# RP2350 register map
Vendor: Raspberry Pi; Series: RP; File version: 0.1
CPU: CM33 r1p0, little endian, MPU, FPU, DSP, VTOR, 4 interrupt priority bits, 52 interrupts, 8 SAU regions
Registers are 32-bit, read-write, reset 0x0 unless marked. A register's access mark holds for its fields unless they carry their own. Offsets are from the block's base; [hi:lo] are bit positions; {n}, {i} and the like mark numbered series; 'fields as' and 'values as' point back to an identical list.

## IO_BANK0 — Peripheral description
Base 0x40028000
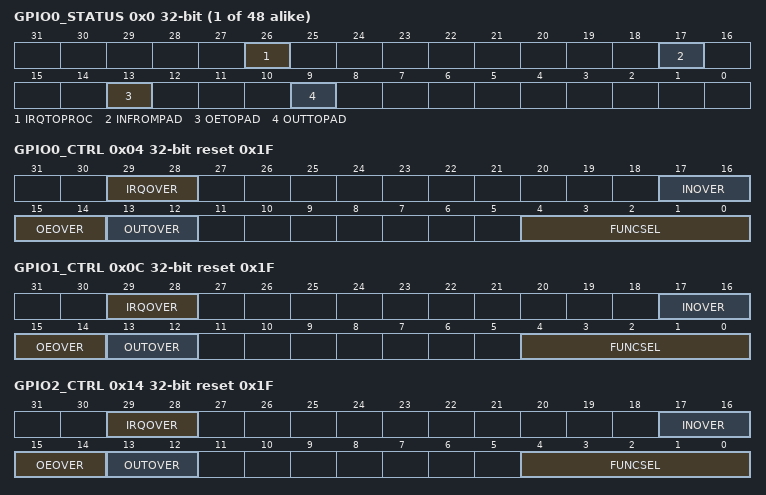
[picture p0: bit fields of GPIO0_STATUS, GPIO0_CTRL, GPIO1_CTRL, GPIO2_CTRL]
{0x0+8i} GPIO{i}_STATUS (i=0..47) — register description
  [26] IRQTOPROC ro — interrupt to processors, after override is applied
  [17] INFROMPAD ro — input signal from pad, before filtering and override are applied
  [13] OETOPAD ro — output enable to pad after register override is applied
  [9] OUTTOPAD ro — output signal to pad after register override is applied
0x04 GPIO0_CTRL reset 0x1F — register description
  [29:28] IRQOVER — Pre-defined description
    0=NORMAL (don't invert the interrupt); 1=INVERT (invert the interrupt); 2=LOW (drive interrupt low); 3=HIGH (drive interrupt high)
  [17:16] INOVER — Pre-defined description
    0=NORMAL (don't invert the peri input); 1=INVERT (invert the peri input); 2=LOW (drive peri input low); 3=HIGH (drive peri input high)
  [15:14] OEOVER — Pre-defined description
    0=NORMAL (drive output enable from peripheral signal selected by funcsel); 1=INVERT (drive output enable from inverse of peripheral signal selected by funcsel); 2=DISABLE (disable output); 3=ENABLE (enable output)
  [13:12] OUTOVER — Pre-defined description
    0=NORMAL (drive output from peripheral signal selected by funcsel); 1=INVERT (drive output from inverse of peripheral signal selected by funcsel); 2=LOW (drive output low); 3=HIGH (drive output high)
  [4:0] FUNCSEL — 0-31 -> selects pin function according to the gpio table 31 == NULL
    0=jtag_tck; 1=spi0_rx; 2=uart0_tx; 3=i2c0_sda; 4=pwm_a_0; 5=siob_proc_0; 6=pio0_0; 7=pio1_0; 8=pio2_0; 9=xip_ss_n_1; 10=usb_muxing_overcurr_detect; 31=null
0x0C GPIO1_CTRL reset 0x1F — register description
  [29:28] IRQOVER — Pre-defined description
    values as GPIO0_CTRL.IRQOVER
  [17:16] INOVER — Pre-defined description
    values as GPIO0_CTRL.INOVER
  [15:14] OEOVER — Pre-defined description
    values as GPIO0_CTRL.OEOVER
  [13:12] OUTOVER — Pre-defined description
    values as GPIO0_CTRL.OUTOVER
  [4:0] FUNCSEL — 0-31 -> selects pin function according to the gpio table 31 == NULL
    0=jtag_tms; 1=spi0_ss_n; 2=uart0_rx; 3=i2c0_scl; 4=pwm_b_0; 5=siob_proc_1; 6=pio0_1; 7=pio1_1; 8=pio2_1; 9=coresight_traceclk; 10=usb_muxing_vbus_detect; 31=null
0x14 GPIO2_CTRL reset 0x1F — register description
  [29:28] IRQOVER — Pre-defined description
    values as GPIO0_CTRL.IRQOVER
  [17:16] INOVER — Pre-defined description
    values as GPIO0_CTRL.INOVER
  [15:14] OEOVER — Pre-defined description
    values as GPIO0_CTRL.OEOVER
  [13:12] OUTOVER — Pre-defined description
    values as GPIO0_CTRL.OUTOVER
  [4:0] FUNCSEL — 0-31 -> selects pin function according to the gpio table 31 == NULL
    0=jtag_tdi; 1=spi0_sclk; 2=uart0_cts; 3=i2c1_sda; 4=pwm_a_1; 5=siob_proc_2; 6=pio0_2; 7=pio1_2; 8=pio2_2; 9=coresight_tracedata_0; 10=usb_muxing_vbus_en; 11=uart0_tx; 31=null
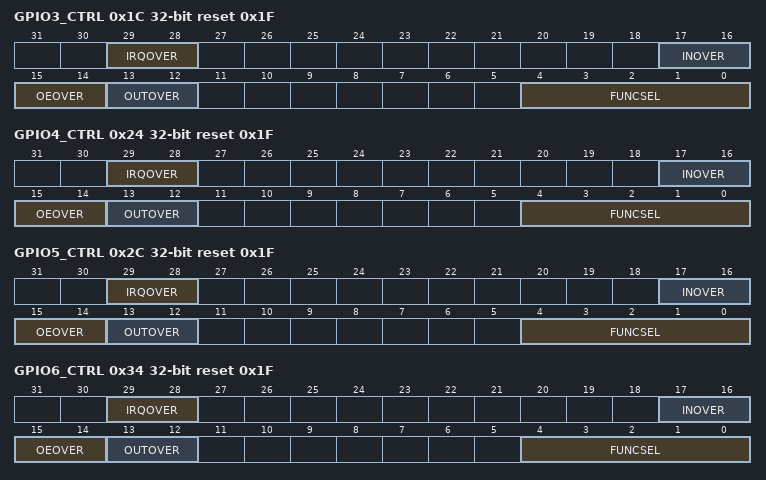
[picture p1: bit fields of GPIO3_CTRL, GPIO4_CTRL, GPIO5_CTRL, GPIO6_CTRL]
0x1C GPIO3_CTRL reset 0x1F — register description
  [29:28] IRQOVER — Pre-defined description
    values as GPIO0_CTRL.IRQOVER
  [17:16] INOVER — Pre-defined description
    values as GPIO0_CTRL.INOVER
  [15:14] OEOVER — Pre-defined description
    values as GPIO0_CTRL.OEOVER
  [13:12] OUTOVER — Pre-defined description
    values as GPIO0_CTRL.OUTOVER
  [4:0] FUNCSEL — 0-31 -> selects pin function according to the gpio table 31 == NULL
    0=jtag_tdo; 1=spi0_tx; 2=uart0_rts; 3=i2c1_scl; 4=pwm_b_1; 5=siob_proc_3; 6=pio0_3; 7=pio1_3; 8=pio2_3; 9=coresight_tracedata_1; 10=usb_muxing_overcurr_detect; 11=uart0_rx; 31=null
0x24 GPIO4_CTRL reset 0x1F — register description
  [29:28] IRQOVER — Pre-defined description
    values as GPIO0_CTRL.IRQOVER
  [17:16] INOVER — Pre-defined description
    values as GPIO0_CTRL.INOVER
  [15:14] OEOVER — Pre-defined description
    values as GPIO0_CTRL.OEOVER
  [13:12] OUTOVER — Pre-defined description
    values as GPIO0_CTRL.OUTOVER
  [4:0] FUNCSEL — 0-31 -> selects pin function according to the gpio table 31 == NULL
    1=spi0_rx; 2=uart1_tx; 3=i2c0_sda; 4=pwm_a_2; 5=siob_proc_4; 6=pio0_4; 7=pio1_4; 8=pio2_4; 9=coresight_tracedata_2; 10=usb_muxing_vbus_detect; 31=null
0x2C GPIO5_CTRL reset 0x1F — register description
  [29:28] IRQOVER — Pre-defined description
    values as GPIO0_CTRL.IRQOVER
  [17:16] INOVER — Pre-defined description
    values as GPIO0_CTRL.INOVER
  [15:14] OEOVER — Pre-defined description
    values as GPIO0_CTRL.OEOVER
  [13:12] OUTOVER — Pre-defined description
    values as GPIO0_CTRL.OUTOVER
  [4:0] FUNCSEL — 0-31 -> selects pin function according to the gpio table 31 == NULL
    1=spi0_ss_n; 2=uart1_rx; 3=i2c0_scl; 4=pwm_b_2; 5=siob_proc_5; 6=pio0_5; 7=pio1_5; 8=pio2_5; 9=coresight_tracedata_3; 10=usb_muxing_vbus_en; 31=null
0x34 GPIO6_CTRL reset 0x1F — register description
  [29:28] IRQOVER — Pre-defined description
    values as GPIO0_CTRL.IRQOVER
  [17:16] INOVER — Pre-defined description
    values as GPIO0_CTRL.INOVER
  [15:14] OEOVER — Pre-defined description
    values as GPIO0_CTRL.OEOVER
  [13:12] OUTOVER — Pre-defined description
    values as GPIO0_CTRL.OUTOVER
  [4:0] FUNCSEL — 0-31 -> selects pin function according to the gpio table 31 == NULL
    1=spi0_sclk; 2=uart1_cts; 3=i2c1_sda; 4=pwm_a_3; 5=siob_proc_6; 6=pio0_6; 7=pio1_6; 8=pio2_6; 10=usb_muxing_overcurr_detect; 11=uart1_tx; 31=null
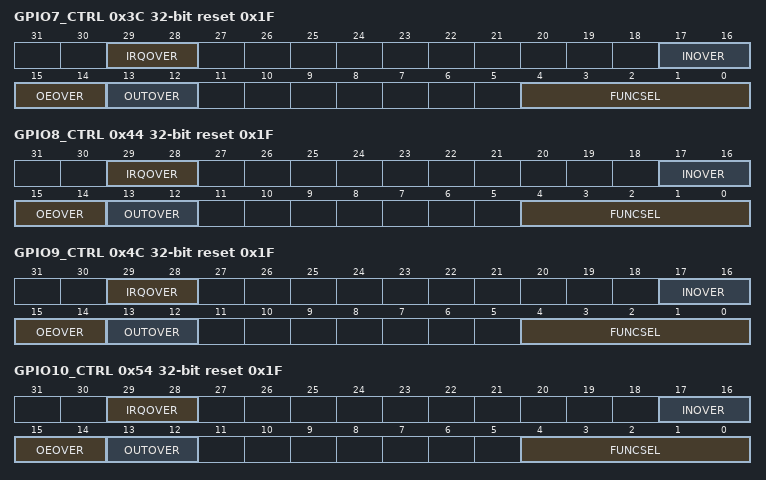
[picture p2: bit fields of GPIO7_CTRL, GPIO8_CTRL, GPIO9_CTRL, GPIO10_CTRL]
0x3C GPIO7_CTRL reset 0x1F — register description
  [29:28] IRQOVER — Pre-defined description
    values as GPIO0_CTRL.IRQOVER
  [17:16] INOVER — Pre-defined description
    values as GPIO0_CTRL.INOVER
  [15:14] OEOVER — Pre-defined description
    values as GPIO0_CTRL.OEOVER
  [13:12] OUTOVER — Pre-defined description
    values as GPIO0_CTRL.OUTOVER
  [4:0] FUNCSEL — 0-31 -> selects pin function according to the gpio table 31 == NULL
    1=spi0_tx; 2=uart1_rts; 3=i2c1_scl; 4=pwm_b_3; 5=siob_proc_7; 6=pio0_7; 7=pio1_7; 8=pio2_7; 10=usb_muxing_vbus_detect; 11=uart1_rx; 31=null
0x44 GPIO8_CTRL reset 0x1F — register description
  [29:28] IRQOVER — Pre-defined description
    values as GPIO0_CTRL.IRQOVER
  [17:16] INOVER — Pre-defined description
    values as GPIO0_CTRL.INOVER
  [15:14] OEOVER — Pre-defined description
    values as GPIO0_CTRL.OEOVER
  [13:12] OUTOVER — Pre-defined description
    values as GPIO0_CTRL.OUTOVER
  [4:0] FUNCSEL — 0-31 -> selects pin function according to the gpio table 31 == NULL
    1=spi1_rx; 2=uart1_tx; 3=i2c0_sda; 4=pwm_a_4; 5=siob_proc_8; 6=pio0_8; 7=pio1_8; 8=pio2_8; 9=xip_ss_n_1; 10=usb_muxing_vbus_en; 31=null
0x4C GPIO9_CTRL reset 0x1F — register description
  [29:28] IRQOVER — Pre-defined description
    values as GPIO0_CTRL.IRQOVER
  [17:16] INOVER — Pre-defined description
    values as GPIO0_CTRL.INOVER
  [15:14] OEOVER — Pre-defined description
    values as GPIO0_CTRL.OEOVER
  [13:12] OUTOVER — Pre-defined description
    values as GPIO0_CTRL.OUTOVER
  [4:0] FUNCSEL — 0-31 -> selects pin function according to the gpio table 31 == NULL
    1=spi1_ss_n; 2=uart1_rx; 3=i2c0_scl; 4=pwm_b_4; 5=siob_proc_9; 6=pio0_9; 7=pio1_9; 8=pio2_9; 10=usb_muxing_overcurr_detect; 31=null
0x54 GPIO10_CTRL reset 0x1F — register description
  [29:28] IRQOVER — Pre-defined description
    values as GPIO0_CTRL.IRQOVER
  [17:16] INOVER — Pre-defined description
    values as GPIO0_CTRL.INOVER
  [15:14] OEOVER — Pre-defined description
    values as GPIO0_CTRL.OEOVER
  [13:12] OUTOVER — Pre-defined description
    values as GPIO0_CTRL.OUTOVER
  [4:0] FUNCSEL — 0-31 -> selects pin function according to the gpio table 31 == NULL
    1=spi1_sclk; 2=uart1_cts; 3=i2c1_sda; 4=pwm_a_5; 5=siob_proc_10; 6=pio0_10; 7=pio1_10; 8=pio2_10; 10=usb_muxing_vbus_detect; 11=uart1_tx; 31=null
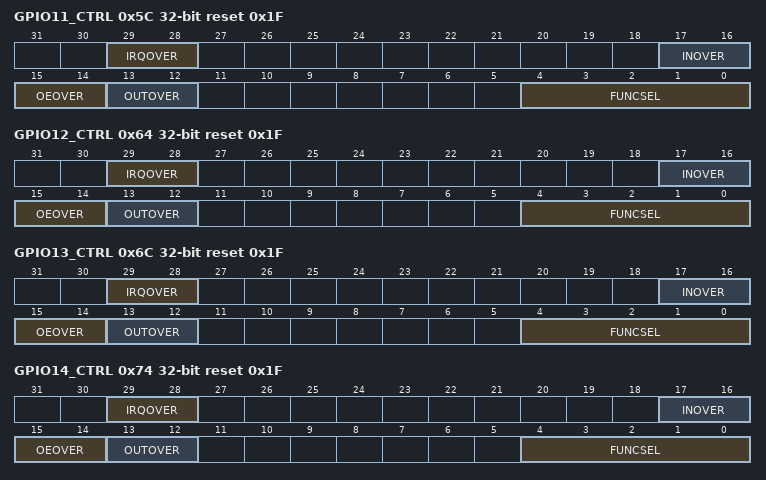
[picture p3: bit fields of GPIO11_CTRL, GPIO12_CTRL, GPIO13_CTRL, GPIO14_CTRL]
0x5C GPIO11_CTRL reset 0x1F — register description
  [29:28] IRQOVER — Pre-defined description
    values as GPIO0_CTRL.IRQOVER
  [17:16] INOVER — Pre-defined description
    values as GPIO0_CTRL.INOVER
  [15:14] OEOVER — Pre-defined description
    values as GPIO0_CTRL.OEOVER
  [13:12] OUTOVER — Pre-defined description
    values as GPIO0_CTRL.OUTOVER
  [4:0] FUNCSEL — 0-31 -> selects pin function according to the gpio table 31 == NULL
    1=spi1_tx; 2=uart1_rts; 3=i2c1_scl; 4=pwm_b_5; 5=siob_proc_11; 6=pio0_11; 7=pio1_11; 8=pio2_11; 10=usb_muxing_vbus_en; 11=uart1_rx; 31=null
0x64 GPIO12_CTRL reset 0x1F — register description
  [29:28] IRQOVER — Pre-defined description
    values as GPIO0_CTRL.IRQOVER
  [17:16] INOVER — Pre-defined description
    values as GPIO0_CTRL.INOVER
  [15:14] OEOVER — Pre-defined description
    values as GPIO0_CTRL.OEOVER
  [13:12] OUTOVER — Pre-defined description
    values as GPIO0_CTRL.OUTOVER
  [4:0] FUNCSEL — 0-31 -> selects pin function according to the gpio table 31 == NULL
    0=hstx_0; 1=spi1_rx; 2=uart0_tx; 3=i2c0_sda; 4=pwm_a_6; 5=siob_proc_12; 6=pio0_12; 7=pio1_12; 8=pio2_12; 9=clocks_gpin_0; 10=usb_muxing_overcurr_detect; 31=null
0x6C GPIO13_CTRL reset 0x1F — register description
  [29:28] IRQOVER — Pre-defined description
    values as GPIO0_CTRL.IRQOVER
  [17:16] INOVER — Pre-defined description
    values as GPIO0_CTRL.INOVER
  [15:14] OEOVER — Pre-defined description
    values as GPIO0_CTRL.OEOVER
  [13:12] OUTOVER — Pre-defined description
    values as GPIO0_CTRL.OUTOVER
  [4:0] FUNCSEL — 0-31 -> selects pin function according to the gpio table 31 == NULL
    0=hstx_1; 1=spi1_ss_n; 2=uart0_rx; 3=i2c0_scl; 4=pwm_b_6; 5=siob_proc_13; 6=pio0_13; 7=pio1_13; 8=pio2_13; 9=clocks_gpout_0; 10=usb_muxing_vbus_detect; 31=null
0x74 GPIO14_CTRL reset 0x1F — register description
  [29:28] IRQOVER — Pre-defined description
    values as GPIO0_CTRL.IRQOVER
  [17:16] INOVER — Pre-defined description
    values as GPIO0_CTRL.INOVER
  [15:14] OEOVER — Pre-defined description
    values as GPIO0_CTRL.OEOVER
  [13:12] OUTOVER — Pre-defined description
    values as GPIO0_CTRL.OUTOVER
  [4:0] FUNCSEL — 0-31 -> selects pin function according to the gpio table 31 == NULL
    0=hstx_2; 1=spi1_sclk; 2=uart0_cts; 3=i2c1_sda; 4=pwm_a_7; 5=siob_proc_14; 6=pio0_14; 7=pio1_14; 8=pio2_14; 9=clocks_gpin_1; 10=usb_muxing_vbus_en; 11=uart0_tx; 31=null
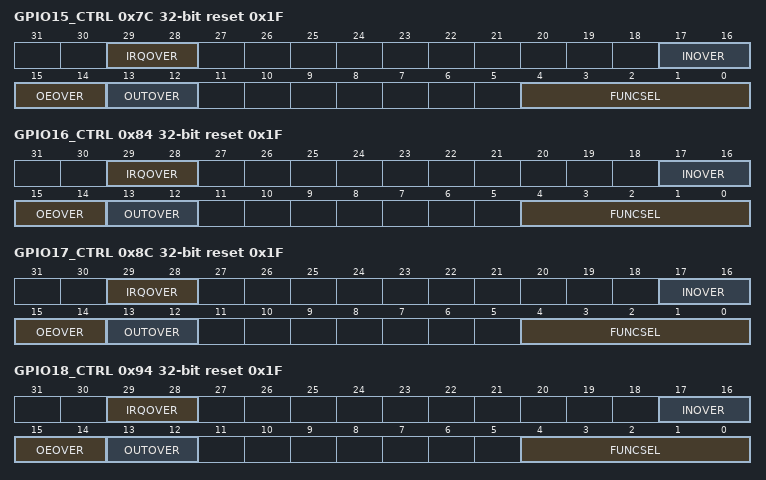
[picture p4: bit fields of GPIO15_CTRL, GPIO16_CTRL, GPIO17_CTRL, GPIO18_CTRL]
0x7C GPIO15_CTRL reset 0x1F — register description
  [29:28] IRQOVER — Pre-defined description
    values as GPIO0_CTRL.IRQOVER
  [17:16] INOVER — Pre-defined description
    values as GPIO0_CTRL.INOVER
  [15:14] OEOVER — Pre-defined description
    values as GPIO0_CTRL.OEOVER
  [13:12] OUTOVER — Pre-defined description
    values as GPIO0_CTRL.OUTOVER
  [4:0] FUNCSEL — 0-31 -> selects pin function according to the gpio table 31 == NULL
    0=hstx_3; 1=spi1_tx; 2=uart0_rts; 3=i2c1_scl; 4=pwm_b_7; 5=siob_proc_15; 6=pio0_15; 7=pio1_15; 8=pio2_15; 9=clocks_gpout_1; 10=usb_muxing_overcurr_detect; 11=uart0_rx; 31=null
0x84 GPIO16_CTRL reset 0x1F — register description
  [29:28] IRQOVER — Pre-defined description
    values as GPIO0_CTRL.IRQOVER
  [17:16] INOVER — Pre-defined description
    values as GPIO0_CTRL.INOVER
  [15:14] OEOVER — Pre-defined description
    values as GPIO0_CTRL.OEOVER
  [13:12] OUTOVER — Pre-defined description
    values as GPIO0_CTRL.OUTOVER
  [4:0] FUNCSEL — 0-31 -> selects pin function according to the gpio table 31 == NULL
    0=hstx_4; 1=spi0_rx; 2=uart0_tx; 3=i2c0_sda; 4=pwm_a_0; 5=siob_proc_16; 6=pio0_16; 7=pio1_16; 8=pio2_16; 10=usb_muxing_vbus_detect; 31=null
0x8C GPIO17_CTRL reset 0x1F — register description
  [29:28] IRQOVER — Pre-defined description
    values as GPIO0_CTRL.IRQOVER
  [17:16] INOVER — Pre-defined description
    values as GPIO0_CTRL.INOVER
  [15:14] OEOVER — Pre-defined description
    values as GPIO0_CTRL.OEOVER
  [13:12] OUTOVER — Pre-defined description
    values as GPIO0_CTRL.OUTOVER
  [4:0] FUNCSEL — 0-31 -> selects pin function according to the gpio table 31 == NULL
    0=hstx_5; 1=spi0_ss_n; 2=uart0_rx; 3=i2c0_scl; 4=pwm_b_0; 5=siob_proc_17; 6=pio0_17; 7=pio1_17; 8=pio2_17; 10=usb_muxing_vbus_en; 31=null
0x94 GPIO18_CTRL reset 0x1F — register description
  [29:28] IRQOVER — Pre-defined description
    values as GPIO0_CTRL.IRQOVER
  [17:16] INOVER — Pre-defined description
    values as GPIO0_CTRL.INOVER
  [15:14] OEOVER — Pre-defined description
    values as GPIO0_CTRL.OEOVER
  [13:12] OUTOVER — Pre-defined description
    values as GPIO0_CTRL.OUTOVER
  [4:0] FUNCSEL — 0-31 -> selects pin function according to the gpio table 31 == NULL
    0=hstx_6; 1=spi0_sclk; 2=uart0_cts; 3=i2c1_sda; 4=pwm_a_1; 5=siob_proc_18; 6=pio0_18; 7=pio1_18; 8=pio2_18; 10=usb_muxing_overcurr_detect; 11=uart0_tx; 31=null
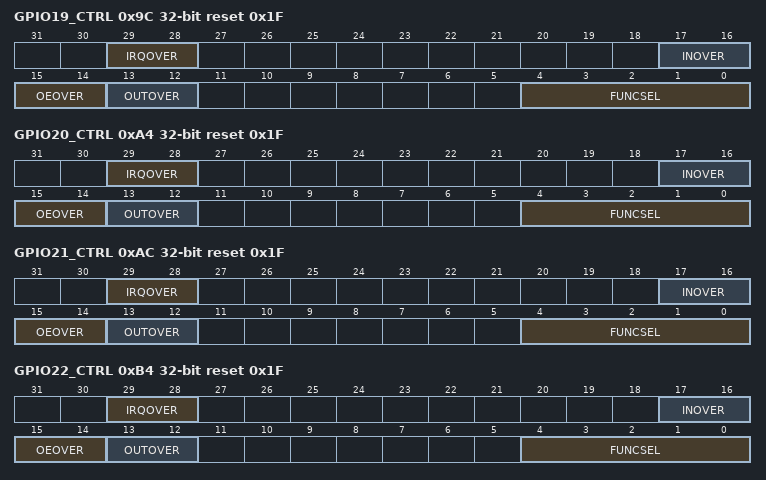
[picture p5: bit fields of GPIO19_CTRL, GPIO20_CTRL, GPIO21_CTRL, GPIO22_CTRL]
0x9C GPIO19_CTRL reset 0x1F — register description
  [29:28] IRQOVER — Pre-defined description
    values as GPIO0_CTRL.IRQOVER
  [17:16] INOVER — Pre-defined description
    values as GPIO0_CTRL.INOVER
  [15:14] OEOVER — Pre-defined description
    values as GPIO0_CTRL.OEOVER
  [13:12] OUTOVER — Pre-defined description
    values as GPIO0_CTRL.OUTOVER
  [4:0] FUNCSEL — 0-31 -> selects pin function according to the gpio table 31 == NULL
    0=hstx_7; 1=spi0_tx; 2=uart0_rts; 3=i2c1_scl; 4=pwm_b_1; 5=siob_proc_19; 6=pio0_19; 7=pio1_19; 8=pio2_19; 9=xip_ss_n_1; 10=usb_muxing_vbus_detect; 11=uart0_rx; 31=null
0xA4 GPIO20_CTRL reset 0x1F — register description
  [29:28] IRQOVER — Pre-defined description
    values as GPIO0_CTRL.IRQOVER
  [17:16] INOVER — Pre-defined description
    values as GPIO0_CTRL.INOVER
  [15:14] OEOVER — Pre-defined description
    values as GPIO0_CTRL.OEOVER
  [13:12] OUTOVER — Pre-defined description
    values as GPIO0_CTRL.OUTOVER
  [4:0] FUNCSEL — 0-31 -> selects pin function according to the gpio table 31 == NULL
    1=spi0_rx; 2=uart1_tx; 3=i2c0_sda; 4=pwm_a_2; 5=siob_proc_20; 6=pio0_20; 7=pio1_20; 8=pio2_20; 9=clocks_gpin_0; 10=usb_muxing_vbus_en; 31=null
0xAC GPIO21_CTRL reset 0x1F — register description
  [29:28] IRQOVER — Pre-defined description
    values as GPIO0_CTRL.IRQOVER
  [17:16] INOVER — Pre-defined description
    values as GPIO0_CTRL.INOVER
  [15:14] OEOVER — Pre-defined description
    values as GPIO0_CTRL.OEOVER
  [13:12] OUTOVER — Pre-defined description
    values as GPIO0_CTRL.OUTOVER
  [4:0] FUNCSEL — 0-31 -> selects pin function according to the gpio table 31 == NULL
    1=spi0_ss_n; 2=uart1_rx; 3=i2c0_scl; 4=pwm_b_2; 5=siob_proc_21; 6=pio0_21; 7=pio1_21; 8=pio2_21; 9=clocks_gpout_0; 10=usb_muxing_overcurr_detect; 31=null
0xB4 GPIO22_CTRL reset 0x1F — register description
  [29:28] IRQOVER — Pre-defined description
    values as GPIO0_CTRL.IRQOVER
  [17:16] INOVER — Pre-defined description
    values as GPIO0_CTRL.INOVER
  [15:14] OEOVER — Pre-defined description
    values as GPIO0_CTRL.OEOVER
  [13:12] OUTOVER — Pre-defined description
    values as GPIO0_CTRL.OUTOVER
  [4:0] FUNCSEL — 0-31 -> selects pin function according to the gpio table 31 == NULL
    1=spi0_sclk; 2=uart1_cts; 3=i2c1_sda; 4=pwm_a_3; 5=siob_proc_22; 6=pio0_22; 7=pio1_22; 8=pio2_22; 9=clocks_gpin_1; 10=usb_muxing_vbus_detect; 11=uart1_tx; 31=null
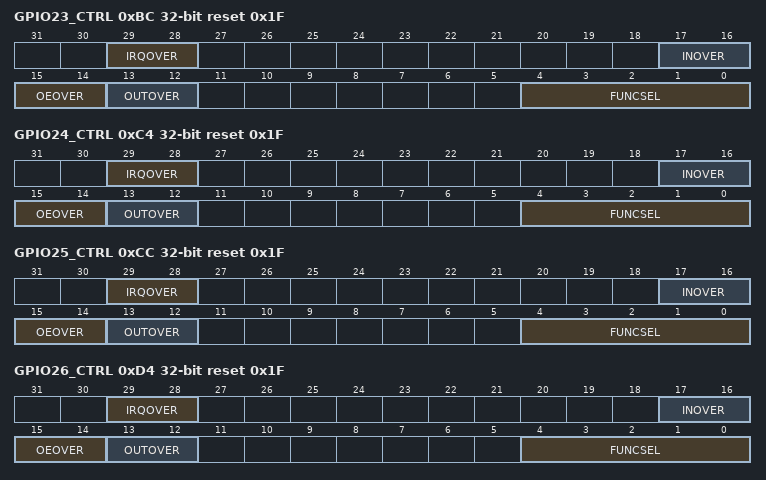
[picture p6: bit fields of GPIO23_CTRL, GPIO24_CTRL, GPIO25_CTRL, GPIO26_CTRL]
0xBC GPIO23_CTRL reset 0x1F — register description
  [29:28] IRQOVER — Pre-defined description
    values as GPIO0_CTRL.IRQOVER
  [17:16] INOVER — Pre-defined description
    values as GPIO0_CTRL.INOVER
  [15:14] OEOVER — Pre-defined description
    values as GPIO0_CTRL.OEOVER
  [13:12] OUTOVER — Pre-defined description
    values as GPIO0_CTRL.OUTOVER
  [4:0] FUNCSEL — 0-31 -> selects pin function according to the gpio table 31 == NULL
    1=spi0_tx; 2=uart1_rts; 3=i2c1_scl; 4=pwm_b_3; 5=siob_proc_23; 6=pio0_23; 7=pio1_23; 8=pio2_23; 9=clocks_gpout_1; 10=usb_muxing_vbus_en; 11=uart1_rx; 31=null
0xC4 GPIO24_CTRL reset 0x1F — register description
  [29:28] IRQOVER — Pre-defined description
    values as GPIO0_CTRL.IRQOVER
  [17:16] INOVER — Pre-defined description
    values as GPIO0_CTRL.INOVER
  [15:14] OEOVER — Pre-defined description
    values as GPIO0_CTRL.OEOVER
  [13:12] OUTOVER — Pre-defined description
    values as GPIO0_CTRL.OUTOVER
  [4:0] FUNCSEL — 0-31 -> selects pin function according to the gpio table 31 == NULL
    1=spi1_rx; 2=uart1_tx; 3=i2c0_sda; 4=pwm_a_4; 5=siob_proc_24; 6=pio0_24; 7=pio1_24; 8=pio2_24; 9=clocks_gpout_2; 10=usb_muxing_overcurr_detect; 31=null
0xCC GPIO25_CTRL reset 0x1F — register description
  [29:28] IRQOVER — Pre-defined description
    values as GPIO0_CTRL.IRQOVER
  [17:16] INOVER — Pre-defined description
    values as GPIO0_CTRL.INOVER
  [15:14] OEOVER — Pre-defined description
    values as GPIO0_CTRL.OEOVER
  [13:12] OUTOVER — Pre-defined description
    values as GPIO0_CTRL.OUTOVER
  [4:0] FUNCSEL — 0-31 -> selects pin function according to the gpio table 31 == NULL
    1=spi1_ss_n; 2=uart1_rx; 3=i2c0_scl; 4=pwm_b_4; 5=siob_proc_25; 6=pio0_25; 7=pio1_25; 8=pio2_25; 9=clocks_gpout_3; 10=usb_muxing_vbus_detect; 31=null
0xD4 GPIO26_CTRL reset 0x1F — register description
  [29:28] IRQOVER — Pre-defined description
    values as GPIO0_CTRL.IRQOVER
  [17:16] INOVER — Pre-defined description
    values as GPIO0_CTRL.INOVER
  [15:14] OEOVER — Pre-defined description
    values as GPIO0_CTRL.OEOVER
  [13:12] OUTOVER — Pre-defined description
    values as GPIO0_CTRL.OUTOVER
  [4:0] FUNCSEL — 0-31 -> selects pin function according to the gpio table 31 == NULL
    1=spi1_sclk; 2=uart1_cts; 3=i2c1_sda; 4=pwm_a_5; 5=siob_proc_26; 6=pio0_26; 7=pio1_26; 8=pio2_26; 10=usb_muxing_vbus_en; 11=uart1_tx; 31=null
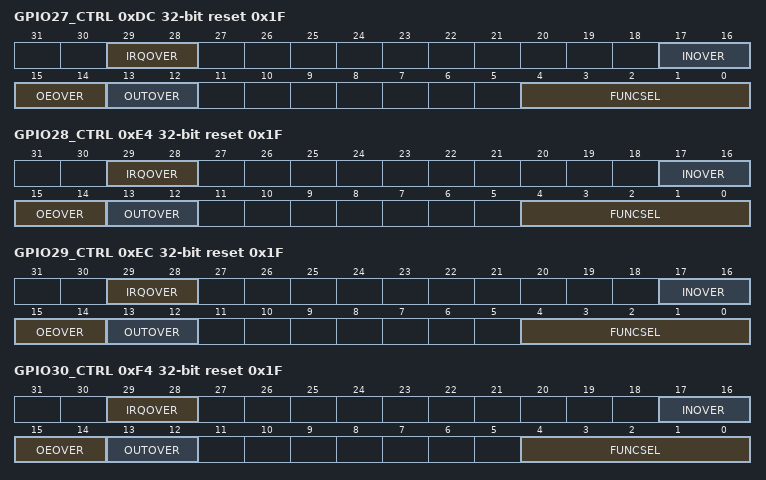
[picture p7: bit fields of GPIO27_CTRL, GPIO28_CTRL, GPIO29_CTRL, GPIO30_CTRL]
0xDC GPIO27_CTRL reset 0x1F — register description
  [29:28] IRQOVER — Pre-defined description
    values as GPIO0_CTRL.IRQOVER
  [17:16] INOVER — Pre-defined description
    values as GPIO0_CTRL.INOVER
  [15:14] OEOVER — Pre-defined description
    values as GPIO0_CTRL.OEOVER
  [13:12] OUTOVER — Pre-defined description
    values as GPIO0_CTRL.OUTOVER
  [4:0] FUNCSEL — 0-31 -> selects pin function according to the gpio table 31 == NULL
    1=spi1_tx; 2=uart1_rts; 3=i2c1_scl; 4=pwm_b_5; 5=siob_proc_27; 6=pio0_27; 7=pio1_27; 8=pio2_27; 10=usb_muxing_overcurr_detect; 11=uart1_rx; 31=null
0xE4 GPIO28_CTRL reset 0x1F — register description
  [29:28] IRQOVER — Pre-defined description
    values as GPIO0_CTRL.IRQOVER
  [17:16] INOVER — Pre-defined description
    values as GPIO0_CTRL.INOVER
  [15:14] OEOVER — Pre-defined description
    values as GPIO0_CTRL.OEOVER
  [13:12] OUTOVER — Pre-defined description
    values as GPIO0_CTRL.OUTOVER
  [4:0] FUNCSEL — 0-31 -> selects pin function according to the gpio table 31 == NULL
    1=spi1_rx; 2=uart0_tx; 3=i2c0_sda; 4=pwm_a_6; 5=siob_proc_28; 6=pio0_28; 7=pio1_28; 8=pio2_28; 10=usb_muxing_vbus_detect; 31=null
0xEC GPIO29_CTRL reset 0x1F — register description
  [29:28] IRQOVER — Pre-defined description
    values as GPIO0_CTRL.IRQOVER
  [17:16] INOVER — Pre-defined description
    values as GPIO0_CTRL.INOVER
  [15:14] OEOVER — Pre-defined description
    values as GPIO0_CTRL.OEOVER
  [13:12] OUTOVER — Pre-defined description
    values as GPIO0_CTRL.OUTOVER
  [4:0] FUNCSEL — 0-31 -> selects pin function according to the gpio table 31 == NULL
    1=spi1_ss_n; 2=uart0_rx; 3=i2c0_scl; 4=pwm_b_6; 5=siob_proc_29; 6=pio0_29; 7=pio1_29; 8=pio2_29; 10=usb_muxing_vbus_en; 31=null
0xF4 GPIO30_CTRL reset 0x1F — register description
  [29:28] IRQOVER — Pre-defined description
    values as GPIO0_CTRL.IRQOVER
  [17:16] INOVER — Pre-defined description
    values as GPIO0_CTRL.INOVER
  [15:14] OEOVER — Pre-defined description
    values as GPIO0_CTRL.OEOVER
  [13:12] OUTOVER — Pre-defined description
    values as GPIO0_CTRL.OUTOVER
  [4:0] FUNCSEL — 0-31 -> selects pin function according to the gpio table 31 == NULL
    1=spi1_sclk; 2=uart0_cts; 3=i2c1_sda; 4=pwm_a_7; 5=siob_proc_30; 6=pio0_30; 7=pio1_30; 8=pio2_30; 10=usb_muxing_overcurr_detect; 11=uart0_tx; 31=null
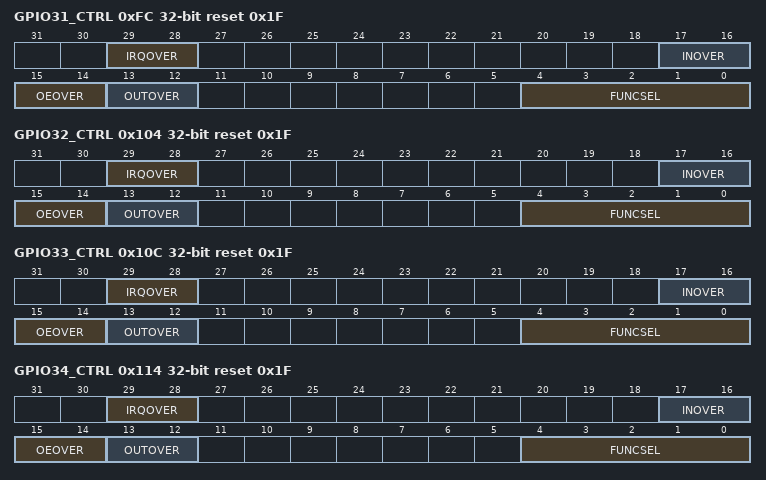
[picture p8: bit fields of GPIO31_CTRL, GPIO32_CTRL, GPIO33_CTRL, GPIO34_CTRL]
0xFC GPIO31_CTRL reset 0x1F — register description
  [29:28] IRQOVER — Pre-defined description
    values as GPIO0_CTRL.IRQOVER
  [17:16] INOVER — Pre-defined description
    values as GPIO0_CTRL.INOVER
  [15:14] OEOVER — Pre-defined description
    values as GPIO0_CTRL.OEOVER
  [13:12] OUTOVER — Pre-defined description
    values as GPIO0_CTRL.OUTOVER
  [4:0] FUNCSEL — 0-31 -> selects pin function according to the gpio table 31 == NULL
    1=spi1_tx; 2=uart0_rts; 3=i2c1_scl; 4=pwm_b_7; 5=siob_proc_31; 6=pio0_31; 7=pio1_31; 8=pio2_31; 10=usb_muxing_vbus_detect; 11=uart0_rx; 31=null
0x104 GPIO32_CTRL reset 0x1F — register description
  [29:28] IRQOVER — Pre-defined description
    values as GPIO0_CTRL.IRQOVER
  [17:16] INOVER — Pre-defined description
    values as GPIO0_CTRL.INOVER
  [15:14] OEOVER — Pre-defined description
    values as GPIO0_CTRL.OEOVER
  [13:12] OUTOVER — Pre-defined description
    values as GPIO0_CTRL.OUTOVER
  [4:0] FUNCSEL — 0-31 -> selects pin function according to the gpio table 31 == NULL
    1=spi0_rx; 2=uart0_tx; 3=i2c0_sda; 4=pwm_a_8; 5=siob_proc_32; 6=pio0_32; 7=pio1_32; 8=pio2_32; 10=usb_muxing_vbus_en; 31=null
0x10C GPIO33_CTRL reset 0x1F — register description
  [29:28] IRQOVER — Pre-defined description
    values as GPIO0_CTRL.IRQOVER
  [17:16] INOVER — Pre-defined description
    values as GPIO0_CTRL.INOVER
  [15:14] OEOVER — Pre-defined description
    values as GPIO0_CTRL.OEOVER
  [13:12] OUTOVER — Pre-defined description
    values as GPIO0_CTRL.OUTOVER
  [4:0] FUNCSEL — 0-31 -> selects pin function according to the gpio table 31 == NULL
    1=spi0_ss_n; 2=uart0_rx; 3=i2c0_scl; 4=pwm_b_8; 5=siob_proc_33; 6=pio0_33; 7=pio1_33; 8=pio2_33; 10=usb_muxing_overcurr_detect; 31=null
0x114 GPIO34_CTRL reset 0x1F — register description
  [29:28] IRQOVER — Pre-defined description
    values as GPIO0_CTRL.IRQOVER
  [17:16] INOVER — Pre-defined description
    values as GPIO0_CTRL.INOVER
  [15:14] OEOVER — Pre-defined description
    values as GPIO0_CTRL.OEOVER
  [13:12] OUTOVER — Pre-defined description
    values as GPIO0_CTRL.OUTOVER
  [4:0] FUNCSEL — 0-31 -> selects pin function according to the gpio table 31 == NULL
    1=spi0_sclk; 2=uart0_cts; 3=i2c1_sda; 4=pwm_a_9; 5=siob_proc_34; 6=pio0_34; 7=pio1_34; 8=pio2_34; 10=usb_muxing_vbus_detect; 11=uart0_tx; 31=null
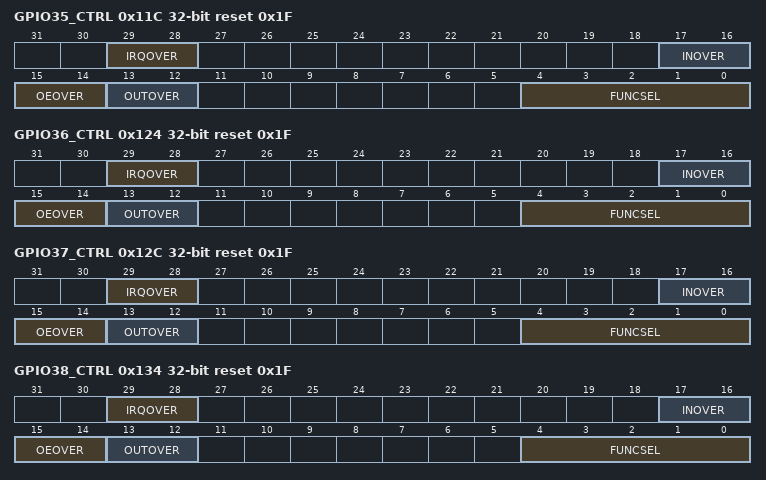
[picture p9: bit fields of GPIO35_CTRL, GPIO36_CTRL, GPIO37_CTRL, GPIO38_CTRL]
0x11C GPIO35_CTRL reset 0x1F — register description
  [29:28] IRQOVER — Pre-defined description
    values as GPIO0_CTRL.IRQOVER
  [17:16] INOVER — Pre-defined description
    values as GPIO0_CTRL.INOVER
  [15:14] OEOVER — Pre-defined description
    values as GPIO0_CTRL.OEOVER
  [13:12] OUTOVER — Pre-defined description
    values as GPIO0_CTRL.OUTOVER
  [4:0] FUNCSEL — 0-31 -> selects pin function according to the gpio table 31 == NULL
    1=spi0_tx; 2=uart0_rts; 3=i2c1_scl; 4=pwm_b_9; 5=siob_proc_35; 6=pio0_35; 7=pio1_35; 8=pio2_35; 10=usb_muxing_vbus_en; 11=uart0_rx; 31=null
0x124 GPIO36_CTRL reset 0x1F — register description
  [29:28] IRQOVER — Pre-defined description
    values as GPIO0_CTRL.IRQOVER
  [17:16] INOVER — Pre-defined description
    values as GPIO0_CTRL.INOVER
  [15:14] OEOVER — Pre-defined description
    values as GPIO0_CTRL.OEOVER
  [13:12] OUTOVER — Pre-defined description
    values as GPIO0_CTRL.OUTOVER
  [4:0] FUNCSEL — 0-31 -> selects pin function according to the gpio table 31 == NULL
    1=spi0_rx; 2=uart1_tx; 3=i2c0_sda; 4=pwm_a_10; 5=siob_proc_36; 6=pio0_36; 7=pio1_36; 8=pio2_36; 10=usb_muxing_overcurr_detect; 31=null
0x12C GPIO37_CTRL reset 0x1F — register description
  [29:28] IRQOVER — Pre-defined description
    values as GPIO0_CTRL.IRQOVER
  [17:16] INOVER — Pre-defined description
    values as GPIO0_CTRL.INOVER
  [15:14] OEOVER — Pre-defined description
    values as GPIO0_CTRL.OEOVER
  [13:12] OUTOVER — Pre-defined description
    values as GPIO0_CTRL.OUTOVER
  [4:0] FUNCSEL — 0-31 -> selects pin function according to the gpio table 31 == NULL
    1=spi0_ss_n; 2=uart1_rx; 3=i2c0_scl; 4=pwm_b_10; 5=siob_proc_37; 6=pio0_37; 7=pio1_37; 8=pio2_37; 10=usb_muxing_vbus_detect; 31=null
0x134 GPIO38_CTRL reset 0x1F — register description
  [29:28] IRQOVER — Pre-defined description
    values as GPIO0_CTRL.IRQOVER
  [17:16] INOVER — Pre-defined description
    values as GPIO0_CTRL.INOVER
  [15:14] OEOVER — Pre-defined description
    values as GPIO0_CTRL.OEOVER
  [13:12] OUTOVER — Pre-defined description
    values as GPIO0_CTRL.OUTOVER
  [4:0] FUNCSEL — 0-31 -> selects pin function according to the gpio table 31 == NULL
    1=spi0_sclk; 2=uart1_cts; 3=i2c1_sda; 4=pwm_a_11; 5=siob_proc_38; 6=pio0_38; 7=pio1_38; 8=pio2_38; 10=usb_muxing_vbus_en; 11=uart1_tx; 31=null
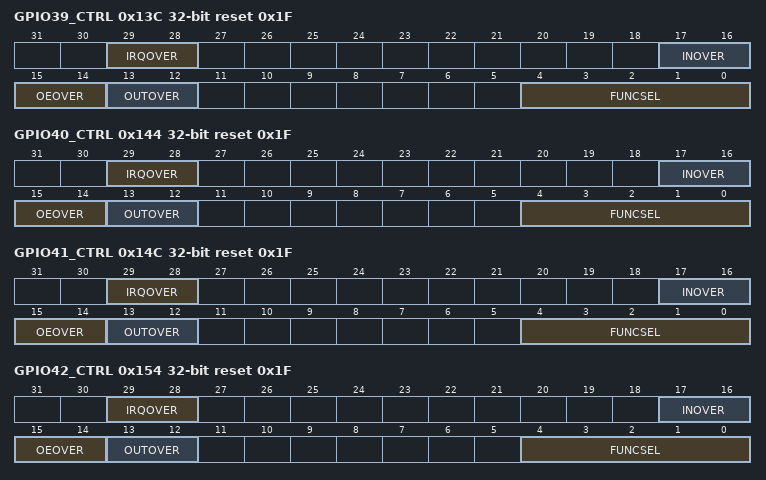
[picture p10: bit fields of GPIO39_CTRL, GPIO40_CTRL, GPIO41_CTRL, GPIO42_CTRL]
0x13C GPIO39_CTRL reset 0x1F — register description
  [29:28] IRQOVER — Pre-defined description
    values as GPIO0_CTRL.IRQOVER
  [17:16] INOVER — Pre-defined description
    values as GPIO0_CTRL.INOVER
  [15:14] OEOVER — Pre-defined description
    values as GPIO0_CTRL.OEOVER
  [13:12] OUTOVER — Pre-defined description
    values as GPIO0_CTRL.OUTOVER
  [4:0] FUNCSEL — 0-31 -> selects pin function according to the gpio table 31 == NULL
    1=spi0_tx; 2=uart1_rts; 3=i2c1_scl; 4=pwm_b_11; 5=siob_proc_39; 6=pio0_39; 7=pio1_39; 8=pio2_39; 10=usb_muxing_overcurr_detect; 11=uart1_rx; 31=null
0x144 GPIO40_CTRL reset 0x1F — register description
  [29:28] IRQOVER — Pre-defined description
    values as GPIO0_CTRL.IRQOVER
  [17:16] INOVER — Pre-defined description
    values as GPIO0_CTRL.INOVER
  [15:14] OEOVER — Pre-defined description
    values as GPIO0_CTRL.OEOVER
  [13:12] OUTOVER — Pre-defined description
    values as GPIO0_CTRL.OUTOVER
  [4:0] FUNCSEL — 0-31 -> selects pin function according to the gpio table 31 == NULL
    1=spi1_rx; 2=uart1_tx; 3=i2c0_sda; 4=pwm_a_8; 5=siob_proc_40; 6=pio0_40; 7=pio1_40; 8=pio2_40; 10=usb_muxing_vbus_detect; 31=null
0x14C GPIO41_CTRL reset 0x1F — register description
  [29:28] IRQOVER — Pre-defined description
    values as GPIO0_CTRL.IRQOVER
  [17:16] INOVER — Pre-defined description
    values as GPIO0_CTRL.INOVER
  [15:14] OEOVER — Pre-defined description
    values as GPIO0_CTRL.OEOVER
  [13:12] OUTOVER — Pre-defined description
    values as GPIO0_CTRL.OUTOVER
  [4:0] FUNCSEL — 0-31 -> selects pin function according to the gpio table 31 == NULL
    1=spi1_ss_n; 2=uart1_rx; 3=i2c0_scl; 4=pwm_b_8; 5=siob_proc_41; 6=pio0_41; 7=pio1_41; 8=pio2_41; 10=usb_muxing_vbus_en; 31=null
0x154 GPIO42_CTRL reset 0x1F — register description
  [29:28] IRQOVER — Pre-defined description
    values as GPIO0_CTRL.IRQOVER
  [17:16] INOVER — Pre-defined description
    values as GPIO0_CTRL.INOVER
  [15:14] OEOVER — Pre-defined description
    values as GPIO0_CTRL.OEOVER
  [13:12] OUTOVER — Pre-defined description
    values as GPIO0_CTRL.OUTOVER
  [4:0] FUNCSEL — 0-31 -> selects pin function according to the gpio table 31 == NULL
    1=spi1_sclk; 2=uart1_cts; 3=i2c1_sda; 4=pwm_a_9; 5=siob_proc_42; 6=pio0_42; 7=pio1_42; 8=pio2_42; 10=usb_muxing_overcurr_detect; 11=uart1_tx; 31=null
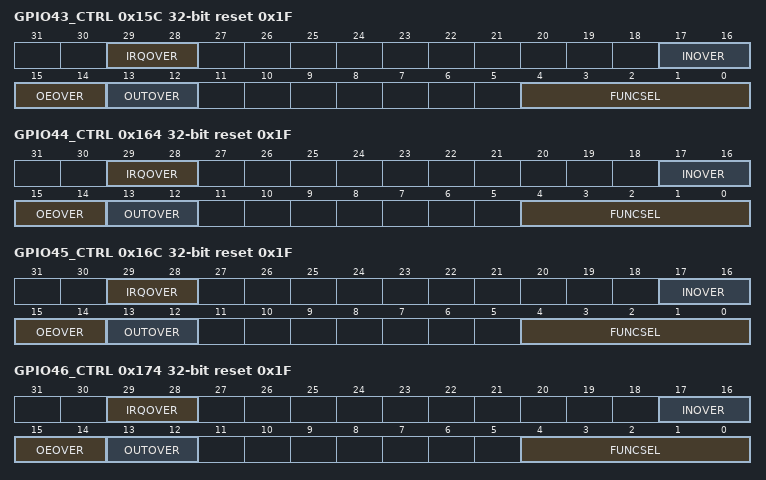
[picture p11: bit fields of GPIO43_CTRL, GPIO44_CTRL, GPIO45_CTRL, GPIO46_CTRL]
0x15C GPIO43_CTRL reset 0x1F — register description
  [29:28] IRQOVER — Pre-defined description
    values as GPIO0_CTRL.IRQOVER
  [17:16] INOVER — Pre-defined description
    values as GPIO0_CTRL.INOVER
  [15:14] OEOVER — Pre-defined description
    values as GPIO0_CTRL.OEOVER
  [13:12] OUTOVER — Pre-defined description
    values as GPIO0_CTRL.OUTOVER
  [4:0] FUNCSEL — 0-31 -> selects pin function according to the gpio table 31 == NULL
    1=spi1_tx; 2=uart1_rts; 3=i2c1_scl; 4=pwm_b_9; 5=siob_proc_43; 6=pio0_43; 7=pio1_43; 8=pio2_43; 10=usb_muxing_vbus_detect; 11=uart1_rx; 31=null
0x164 GPIO44_CTRL reset 0x1F — register description
  [29:28] IRQOVER — Pre-defined description
    values as GPIO0_CTRL.IRQOVER
  [17:16] INOVER — Pre-defined description
    values as GPIO0_CTRL.INOVER
  [15:14] OEOVER — Pre-defined description
    values as GPIO0_CTRL.OEOVER
  [13:12] OUTOVER — Pre-defined description
    values as GPIO0_CTRL.OUTOVER
  [4:0] FUNCSEL — 0-31 -> selects pin function according to the gpio table 31 == NULL
    1=spi1_rx; 2=uart0_tx; 3=i2c0_sda; 4=pwm_a_10; 5=siob_proc_44; 6=pio0_44; 7=pio1_44; 8=pio2_44; 10=usb_muxing_vbus_en; 31=null
0x16C GPIO45_CTRL reset 0x1F — register description
  [29:28] IRQOVER — Pre-defined description
    values as GPIO0_CTRL.IRQOVER
  [17:16] INOVER — Pre-defined description
    values as GPIO0_CTRL.INOVER
  [15:14] OEOVER — Pre-defined description
    values as GPIO0_CTRL.OEOVER
  [13:12] OUTOVER — Pre-defined description
    values as GPIO0_CTRL.OUTOVER
  [4:0] FUNCSEL — 0-31 -> selects pin function according to the gpio table 31 == NULL
    1=spi1_ss_n; 2=uart0_rx; 3=i2c0_scl; 4=pwm_b_10; 5=siob_proc_45; 6=pio0_45; 7=pio1_45; 8=pio2_45; 10=usb_muxing_overcurr_detect; 31=null
0x174 GPIO46_CTRL reset 0x1F — register description
  [29:28] IRQOVER — Pre-defined description
    values as GPIO0_CTRL.IRQOVER
  [17:16] INOVER — Pre-defined description
    values as GPIO0_CTRL.INOVER
  [15:14] OEOVER — Pre-defined description
    values as GPIO0_CTRL.OEOVER
  [13:12] OUTOVER — Pre-defined description
    values as GPIO0_CTRL.OUTOVER
  [4:0] FUNCSEL — 0-31 -> selects pin function according to the gpio table 31 == NULL
    1=spi1_sclk; 2=uart0_cts; 3=i2c1_sda; 4=pwm_a_11; 5=siob_proc_46; 6=pio0_46; 7=pio1_46; 8=pio2_46; 10=usb_muxing_vbus_detect; 11=uart0_tx; 31=null
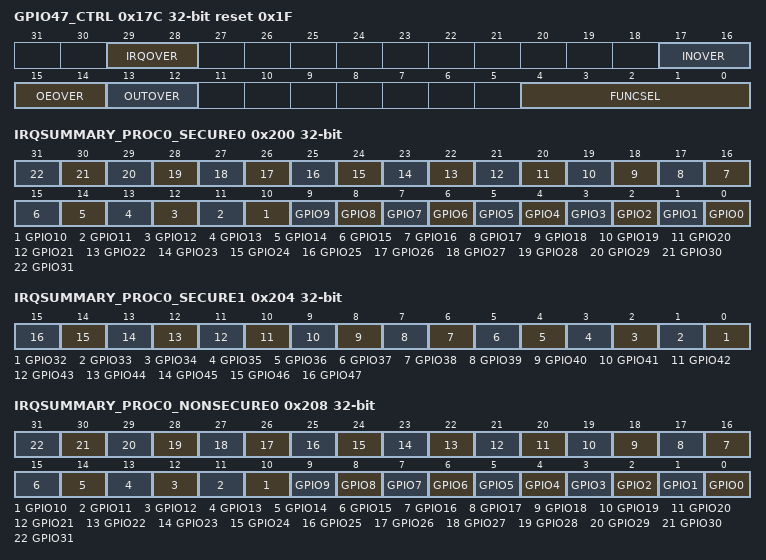
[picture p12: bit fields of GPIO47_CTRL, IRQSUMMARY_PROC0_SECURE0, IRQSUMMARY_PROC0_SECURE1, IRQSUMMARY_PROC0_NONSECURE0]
0x17C GPIO47_CTRL reset 0x1F — register description
  [29:28] IRQOVER — Pre-defined description
    values as GPIO0_CTRL.IRQOVER
  [17:16] INOVER — Pre-defined description
    values as GPIO0_CTRL.INOVER
  [15:14] OEOVER — Pre-defined description
    values as GPIO0_CTRL.OEOVER
  [13:12] OUTOVER — Pre-defined description
    values as GPIO0_CTRL.OUTOVER
  [4:0] FUNCSEL — 0-31 -> selects pin function according to the gpio table 31 == NULL
    1=spi1_tx; 2=uart0_rts; 3=i2c1_scl; 4=pwm_b_11; 5=siob_proc_47; 6=pio0_47; 7=pio1_47; 8=pio2_47; 9=xip_ss_n_1; 10=usb_muxing_vbus_en; 11=uart0_rx; 31=null
0x200 IRQSUMMARY_PROC0_SECURE0 — register description
  [n] GPIO{n} ro (n=0..31) — Pre-defined description
0x204 IRQSUMMARY_PROC0_SECURE1 — register description
  [n-32] GPIO{n} ro (n=32..47) — Pre-defined description
0x208 IRQSUMMARY_PROC0_NONSECURE0 — register description
  [n] GPIO{n} ro (n=0..31) — Pre-defined description
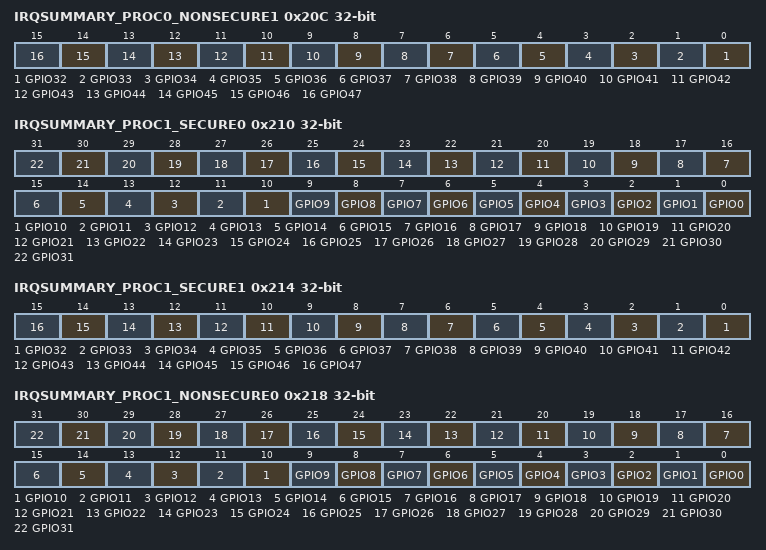
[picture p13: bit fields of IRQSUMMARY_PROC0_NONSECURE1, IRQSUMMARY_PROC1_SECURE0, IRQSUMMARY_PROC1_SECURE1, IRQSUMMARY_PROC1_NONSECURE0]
0x20C IRQSUMMARY_PROC0_NONSECURE1 — register description
  [n-32] GPIO{n} ro (n=32..47) — Pre-defined description
0x210 IRQSUMMARY_PROC1_SECURE0 — register description
  [n] GPIO{n} ro (n=0..31) — Pre-defined description
0x214 IRQSUMMARY_PROC1_SECURE1 — register description
  [n-32] GPIO{n} ro (n=32..47) — Pre-defined description
0x218 IRQSUMMARY_PROC1_NONSECURE0 — register description
  [n] GPIO{n} ro (n=0..31) — Pre-defined description
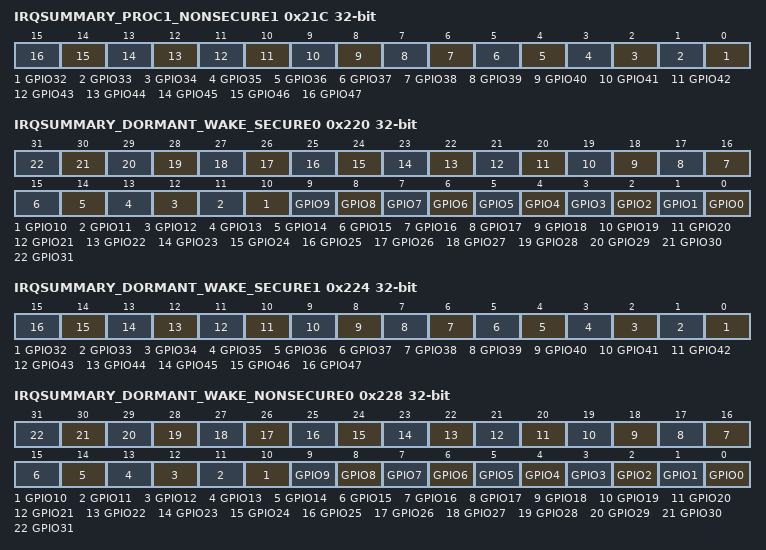
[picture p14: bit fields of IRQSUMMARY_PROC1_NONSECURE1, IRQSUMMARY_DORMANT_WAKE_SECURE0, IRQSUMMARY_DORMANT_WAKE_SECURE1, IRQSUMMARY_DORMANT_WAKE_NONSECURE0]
0x21C IRQSUMMARY_PROC1_NONSECURE1 — register description
  [n-32] GPIO{n} ro (n=32..47) — Pre-defined description
0x220 IRQSUMMARY_DORMANT_WAKE_SECURE0 — register description
  [n] GPIO{n} ro (n=0..31) — Pre-defined description
0x224 IRQSUMMARY_DORMANT_WAKE_SECURE1 — register description
  [n-32] GPIO{n} ro (n=32..47) — Pre-defined description
0x228 IRQSUMMARY_DORMANT_WAKE_NONSECURE0 — register description
  [n] GPIO{n} ro (n=0..31) — Pre-defined description
0x22C IRQSUMMARY_DORMANT_WAKE_NONSECURE1 — register description
  [n-32] GPIO{n} ro (n=32..47) — Pre-defined description
0x230 INTR0 — Raw Interrupts
  [4n+3] GPIO{n}_EDGE_HIGH write-1-clears (n=0..7) — Pre-defined description
  [4n+2] GPIO{n}_EDGE_LOW write-1-clears (n=0..7) — Pre-defined description
  [4n+1] GPIO{n}_LEVEL_HIGH ro (n=0..7) — Pre-defined description
  [4n] GPIO{n}_LEVEL_LOW ro (n=0..7) — Pre-defined description
0x234 INTR1 — Raw Interrupts
  [4n-29] GPIO{n}_EDGE_HIGH write-1-clears (n=8..15) — Pre-defined description
  [4n-30] GPIO{n}_EDGE_LOW write-1-clears (n=8..15) — Pre-defined description
  [4n-31] GPIO{n}_LEVEL_HIGH ro (n=8..15) — Pre-defined description
  [4n-32] GPIO{n}_LEVEL_LOW ro (n=8..15) — Pre-defined description
0x238 INTR2 — Raw Interrupts
  [4n-61] GPIO{n}_EDGE_HIGH write-1-clears (n=16..23) — Pre-defined description
  [4n-62] GPIO{n}_EDGE_LOW write-1-clears (n=16..23) — Pre-defined description
  [4n-63] GPIO{n}_LEVEL_HIGH ro (n=16..23) — Pre-defined description
  [4n-64] GPIO{n}_LEVEL_LOW ro (n=16..23) — Pre-defined description
0x23C INTR3 — Raw Interrupts
  [4n-93] GPIO{n}_EDGE_HIGH write-1-clears (n=24..31) — Pre-defined description
  [4n-94] GPIO{n}_EDGE_LOW write-1-clears (n=24..31) — Pre-defined description
  [4n-95] GPIO{n}_LEVEL_HIGH ro (n=24..31) — Pre-defined description
  [4n-96] GPIO{n}_LEVEL_LOW ro (n=24..31) — Pre-defined description
0x240 INTR4 — Raw Interrupts
  [4n-125] GPIO{n}_EDGE_HIGH write-1-clears (n=32..39) — Pre-defined description
  [4n-126] GPIO{n}_EDGE_LOW write-1-clears (n=32..39) — Pre-defined description
  [4n-127] GPIO{n}_LEVEL_HIGH ro (n=32..39) — Pre-defined description
  [4n-128] GPIO{n}_LEVEL_LOW ro (n=32..39) — Pre-defined description
0x244 INTR5 — Raw Interrupts
  [4n-157] GPIO{n}_EDGE_HIGH write-1-clears (n=40..47) — Pre-defined description
  [4n-158] GPIO{n}_EDGE_LOW write-1-clears (n=40..47) — Pre-defined description
  [4n-159] GPIO{n}_LEVEL_HIGH ro (n=40..47) — Pre-defined description
  [4n-160] GPIO{n}_LEVEL_LOW ro (n=40..47) — Pre-defined description
0x248 PROC0_INTE0 — Interrupt Enable for proc0
  [4n+3] GPIO{n}_EDGE_HIGH (n=0..7) — Pre-defined description
  [4n+2] GPIO{n}_EDGE_LOW (n=0..7) — Pre-defined description
  [4n+1] GPIO{n}_LEVEL_HIGH (n=0..7) — Pre-defined description
  [4n] GPIO{n}_LEVEL_LOW (n=0..7) — Pre-defined description
0x24C PROC0_INTE1 — Interrupt Enable for proc0
  [4n-29] GPIO{n}_EDGE_HIGH (n=8..15) — Pre-defined description
  [4n-30] GPIO{n}_EDGE_LOW (n=8..15) — Pre-defined description
  [4n-31] GPIO{n}_LEVEL_HIGH (n=8..15) — Pre-defined description
  [4n-32] GPIO{n}_LEVEL_LOW (n=8..15) — Pre-defined description
0x250 PROC0_INTE2 — Interrupt Enable for proc0
  [4n-61] GPIO{n}_EDGE_HIGH (n=16..23) — Pre-defined description
  [4n-62] GPIO{n}_EDGE_LOW (n=16..23) — Pre-defined description
  [4n-63] GPIO{n}_LEVEL_HIGH (n=16..23) — Pre-defined description
  [4n-64] GPIO{n}_LEVEL_LOW (n=16..23) — Pre-defined description
0x254 PROC0_INTE3 — Interrupt Enable for proc0
  [4n-93] GPIO{n}_EDGE_HIGH (n=24..31) — Pre-defined description
  [4n-94] GPIO{n}_EDGE_LOW (n=24..31) — Pre-defined description
  [4n-95] GPIO{n}_LEVEL_HIGH (n=24..31) — Pre-defined description
  [4n-96] GPIO{n}_LEVEL_LOW (n=24..31) — Pre-defined description
0x258 PROC0_INTE4 — Interrupt Enable for proc0
  [4n-125] GPIO{n}_EDGE_HIGH (n=32..39) — Pre-defined description
  [4n-126] GPIO{n}_EDGE_LOW (n=32..39) — Pre-defined description
  [4n-127] GPIO{n}_LEVEL_HIGH (n=32..39) — Pre-defined description
  [4n-128] GPIO{n}_LEVEL_LOW (n=32..39) — Pre-defined description
0x25C PROC0_INTE5 — Interrupt Enable for proc0
  [4n-157] GPIO{n}_EDGE_HIGH (n=40..47) — Pre-defined description
  [4n-158] GPIO{n}_EDGE_LOW (n=40..47) — Pre-defined description
  [4n-159] GPIO{n}_LEVEL_HIGH (n=40..47) — Pre-defined description
  [4n-160] GPIO{n}_LEVEL_LOW (n=40..47) — Pre-defined description
0x260 PROC0_INTF0 — Interrupt Force for proc0
  fields as PROC0_INTE0
0x264 PROC0_INTF1 — Interrupt Force for proc0
  fields as PROC0_INTE1
0x268 PROC0_INTF2 — Interrupt Force for proc0
  fields as PROC0_INTE2
0x26C PROC0_INTF3 — Interrupt Force for proc0
  fields as PROC0_INTE3
0x270 PROC0_INTF4 — Interrupt Force for proc0
  fields as PROC0_INTE4
0x274 PROC0_INTF5 — Interrupt Force for proc0
  fields as PROC0_INTE5
0x278 PROC0_INTS0 — Interrupt status after masking & forcing for proc0
  [4n+3] GPIO{n}_EDGE_HIGH ro (n=0..7) — Pre-defined description
  [4n+2] GPIO{n}_EDGE_LOW ro (n=0..7) — Pre-defined description
  [4n+1] GPIO{n}_LEVEL_HIGH ro (n=0..7) — Pre-defined description
  [4n] GPIO{n}_LEVEL_LOW ro (n=0..7) — Pre-defined description
0x27C PROC0_INTS1 — Interrupt status after masking & forcing for proc0
  [4n-29] GPIO{n}_EDGE_HIGH ro (n=8..15) — Pre-defined description
  [4n-30] GPIO{n}_EDGE_LOW ro (n=8..15) — Pre-defined description
  [4n-31] GPIO{n}_LEVEL_HIGH ro (n=8..15) — Pre-defined description
  [4n-32] GPIO{n}_LEVEL_LOW ro (n=8..15) — Pre-defined description
0x280 PROC0_INTS2 — Interrupt status after masking & forcing for proc0
  [4n-61] GPIO{n}_EDGE_HIGH ro (n=16..23) — Pre-defined description
  [4n-62] GPIO{n}_EDGE_LOW ro (n=16..23) — Pre-defined description
  [4n-63] GPIO{n}_LEVEL_HIGH ro (n=16..23) — Pre-defined description
  [4n-64] GPIO{n}_LEVEL_LOW ro (n=16..23) — Pre-defined description
0x284 PROC0_INTS3 — Interrupt status after masking & forcing for proc0
  [4n-93] GPIO{n}_EDGE_HIGH ro (n=24..31) — Pre-defined description
  [4n-94] GPIO{n}_EDGE_LOW ro (n=24..31) — Pre-defined description
  [4n-95] GPIO{n}_LEVEL_HIGH ro (n=24..31) — Pre-defined description
  [4n-96] GPIO{n}_LEVEL_LOW ro (n=24..31) — Pre-defined description
0x288 PROC0_INTS4 — Interrupt status after masking & forcing for proc0
  [4n-125] GPIO{n}_EDGE_HIGH ro (n=32..39) — Pre-defined description
  [4n-126] GPIO{n}_EDGE_LOW ro (n=32..39) — Pre-defined description
  [4n-127] GPIO{n}_LEVEL_HIGH ro (n=32..39) — Pre-defined description
  [4n-128] GPIO{n}_LEVEL_LOW ro (n=32..39) — Pre-defined description
0x28C PROC0_INTS5 — Interrupt status after masking & forcing for proc0
  [4n-157] GPIO{n}_EDGE_HIGH ro (n=40..47) — Pre-defined description
  [4n-158] GPIO{n}_EDGE_LOW ro (n=40..47) — Pre-defined description
  [4n-159] GPIO{n}_LEVEL_HIGH ro (n=40..47) — Pre-defined description
  [4n-160] GPIO{n}_LEVEL_LOW ro (n=40..47) — Pre-defined description
0x290 PROC1_INTE0 — Interrupt Enable for proc1
  fields as PROC0_INTE0
0x294 PROC1_INTE1 — Interrupt Enable for proc1
  fields as PROC0_INTE1
0x298 PROC1_INTE2 — Interrupt Enable for proc1
  fields as PROC0_INTE2
0x29C PROC1_INTE3 — Interrupt Enable for proc1
  fields as PROC0_INTE3
0x2A0 PROC1_INTE4 — Interrupt Enable for proc1
  fields as PROC0_INTE4
0x2A4 PROC1_INTE5 — Interrupt Enable for proc1
  fields as PROC0_INTE5
0x2A8 PROC1_INTF0 — Interrupt Force for proc1
  fields as PROC0_INTE0
0x2AC PROC1_INTF1 — Interrupt Force for proc1
  fields as PROC0_INTE1
0x2B0 PROC1_INTF2 — Interrupt Force for proc1
  fields as PROC0_INTE2
0x2B4 PROC1_INTF3 — Interrupt Force for proc1
  fields as PROC0_INTE3
0x2B8 PROC1_INTF4 — Interrupt Force for proc1
  fields as PROC0_INTE4
0x2BC PROC1_INTF5 — Interrupt Force for proc1
  fields as PROC0_INTE5
0x2C0 PROC1_INTS0 — Interrupt status after masking & forcing for proc1
  fields as PROC0_INTS0
0x2C4 PROC1_INTS1 — Interrupt status after masking & forcing for proc1
  fields as PROC0_INTS1
0x2C8 PROC1_INTS2 — Interrupt status after masking & forcing for proc1
  fields as PROC0_INTS2
0x2CC PROC1_INTS3 — Interrupt status after masking & forcing for proc1
  fields as PROC0_INTS3
0x2D0 PROC1_INTS4 — Interrupt status after masking & forcing for proc1
  fields as PROC0_INTS4
0x2D4 PROC1_INTS5 — Interrupt status after masking & forcing for proc1
  fields as PROC0_INTS5
0x2D8 DORMANT_WAKE_INTE0 — Interrupt Enable for dormant_wake
  fields as PROC0_INTE0
0x2DC DORMANT_WAKE_INTE1 — Interrupt Enable for dormant_wake
  fields as PROC0_INTE1
0x2E0 DORMANT_WAKE_INTE2 — Interrupt Enable for dormant_wake
  fields as PROC0_INTE2
0x2E4 DORMANT_WAKE_INTE3 — Interrupt Enable for dormant_wake
  fields as PROC0_INTE3
0x2E8 DORMANT_WAKE_INTE4 — Interrupt Enable for dormant_wake
  fields as PROC0_INTE4
0x2EC DORMANT_WAKE_INTE5 — Interrupt Enable for dormant_wake
  fields as PROC0_INTE5
0x2F0 DORMANT_WAKE_INTF0 — Interrupt Force for dormant_wake
  fields as PROC0_INTE0
0x2F4 DORMANT_WAKE_INTF1 — Interrupt Force for dormant_wake
  fields as PROC0_INTE1
0x2F8 DORMANT_WAKE_INTF2 — Interrupt Force for dormant_wake
  fields as PROC0_INTE2
0x2FC DORMANT_WAKE_INTF3 — Interrupt Force for dormant_wake
  fields as PROC0_INTE3
0x300 DORMANT_WAKE_INTF4 — Interrupt Force for dormant_wake
  fields as PROC0_INTE4
0x304 DORMANT_WAKE_INTF5 — Interrupt Force for dormant_wake
  fields as PROC0_INTE5
0x308 DORMANT_WAKE_INTS0 — Interrupt status after masking & forcing for dormant_wake
  fields as PROC0_INTS0
0x30C DORMANT_WAKE_INTS1 — Interrupt status after masking & forcing for dormant_wake
  fields as PROC0_INTS1
0x310 DORMANT_WAKE_INTS2 — Interrupt status after masking & forcing for dormant_wake
  fields as PROC0_INTS2
0x314 DORMANT_WAKE_INTS3 — Interrupt status after masking & forcing for dormant_wake
  fields as PROC0_INTS3
0x318 DORMANT_WAKE_INTS4 — Interrupt status after masking & forcing for dormant_wake
  fields as PROC0_INTS4
0x31C DORMANT_WAKE_INTS5 — Interrupt status after masking & forcing for dormant_wake
  fields as PROC0_INTS5
